# LPC178x7x register map
File version: 0.9
CPU: CM3 r0p0, little endian, no MPU, no FPU, 3 interrupt priority bits
Registers are 32-bit, read-write, reset 0x0 unless marked. A register's access mark holds for its fields unless they carry their own. Offsets are from the block's base; [hi:lo] are bit positions; {n}, {i} and the like mark numbered series.

## SYSCON — System and clock control
Base 0x400FC000
0x00 FLASHCFG — Flash Accelerator Configuration Register. Controls flash access timing.
  [15:12] FLASHTIM — Flash access time. The value of this field plus 1 gives the number of CPU clocks used for a flash access. Warning: improper setting of this value may result in incorrect operation of the device. All other values are reserved.
    0=FLASH_ACCESSES_USE_1 (Flash accesses use 1 CPU clock. Use for up to 20 MHz CPU clock with power boost off.); 1=FLASH_ACCESSES_USE_2 (Flash accesses use 2 CPU clocks. Use for up to 40 MHz CPU clock with power boost off.); 2=FLASH_ACCESSES_USE_3 (Flash accesses use 3 CPU clocks. Use for up to 60 MHz CPU clock with power boost off.); 3=FLASH_ACCESSES_USE_4 (Flash accesses use 4 CPU clocks. Use for up to 80 MHz CPU clock with power boost off. Use this setting for operation from 100 to 120 MHz operation with power boost on.); 4=FLASH_ACCESSES_USE_5 (Flash accesses use 5 CPU clocks. Use for up to 100 MHz CPU clock with power boost off.); 5=FLASH_ACCESSES_USE_6 (Flash accesses use 6 CPU clocks. Safe setting for any allowed conditions.)
{0x80+0x20*i} PLL{i}CON (i=0..1) — PLL0 Control register
  [0] PLLE — PLL Enable. When one, and after a valid PLL feed, this bit will activate the related PLL and allow it to lock to the requested frequency. See PLLSTAT register, Table 12.
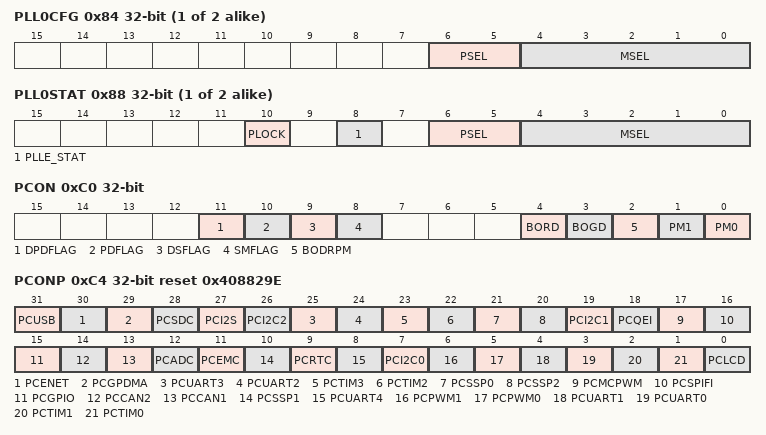
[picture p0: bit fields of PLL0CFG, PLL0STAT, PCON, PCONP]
{0x84+0x20*i} PLL{i}CFG (i=0..1) — PLL0 Configuration register
  [6:5] PSEL — PLL Divider value. Supplies the value "P" in the PLL frequency calculations. Note: For details on selecting the right value for PSEL see Section 3.10.4.
  [4:0] MSEL — PLL Multiplier value. Supplies the value "M" in the PLL frequency calculations. Note: For details on selecting the right value for MSEL see Section 3.10.4.
{0x88+0x20*i} PLL{i}STAT (i=0..1) ro — PLL0 Status register
  [10] PLOCK — Reflects the PLL Lock status. When zero, the related PLL is not locked. When one, the related PLL is locked onto the requested frequency.
  [8] PLLE_STAT — Read-back for the PLL Enable bit. When one, the related PLL is currently activated. When zero, the related PLL is turned off. This bit is automatically cleared when Power-down mode is activated.
  [6:5] PSEL — Read-back for the PLL Divider value. This is the value currently used by the related PLL.
  [4:0] MSEL — Read-back for the PLL Multiplier value. This is the value currently used by the related PLL.
{0x8C+0x20*i} PLL{i}FEED (i=0..1) wo reset not defined — PLL0 Feed register
  [7:0] PLLFEED — The PLL feed sequence must be written to this register in order for the related PLL's configuration and control register changes to take effect.
0xC0 PCON — Power Control register
  [11] DPDFLAG — Deep Power-down entry flag. Set when the Deep Power-down mode is successfully entered. Cleared by software writing a one to this bit.
  [10] PDFLAG — Power-down entry flag. Set when the Power-down mode is successfully entered. Cleared by software writing a one to this bit.
  [9] DSFLAG — Deep Sleep entry flag. Set when the Deep Sleep mode is successfully entered. Cleared by software writing a one to this bit.
  [8] SMFLAG — Sleep Mode entry flag. Set when the Sleep mode is successfully entered. Cleared by software writing a one to this bit.
  [4] BORD — Brown-Out Reset Disable. When BORD is 1, the BOD will not reset the device when the VDD(REG)(3V3) voltage dips goes below the BOD reset trip level. The Brown-Out interrupt is not affected. When BORD is 0, the BOD reset is enabled. See the Section 3.6 for details of Brown-Out detection.
  [3] BOGD — Brown-Out Global Disable. When BOGD is 1, the Brown-Out Detect circuitry is fully disabled at all times, and does not consume power. When 0, the Brown-Out Detect circuitry is enabled. See the System Control Block chapter for details of Brown-Out detection.
  [2] BODRPM — Brown-Out Reduced Power Mode. When BODRPM is 1, the Brown-Out Detect circuitry will be turned off when chip Power-down mode or Deep Sleep mode is entered, resulting in a further reduction in power usage. However, the possibility of using Brown-Out Detect as a wake-up source from the reduced power mode will be lost. When 0, the Brown-Out Detect function remains active during Power-down and Deep Sleep modes. See the System Control Block chapter for details of Brown-Out detection.
  [1] PM1 — Power mode control bit 1. This bit controls entry to the Deep Power-down mode. See Section 3.3.6.1 below for details.
  [0] PM0 — Power mode control bit 0. This bit controls entry to the Power-down mode. See Section 3.3.6.1 below for details.
0xC4 PCONP reset 0x408829E — Power Control for Peripherals
  [31] PCUSB — USB interface power/clock control bit.
  [30] PCENET — Ethernet block power/clock control bit.
  [29] PCGPDMA — GPDMA function power/clock control bit.
  [28] PCSDC — SD Card interface power/clock control bit.
  [27] PCI2S — I2S interface power/clock control bit.
  [26] PCI2C2 — I2C interface 2 power/clock control bit.
  [25] PCUART3 — UART 3 power/clock control bit.
  [24] PCUART2 — UART 2 power/clock control bit.
  [23] PCTIM3 — Timer 3 power/clock control bit.
  [22] PCTIM2 — Timer 2 power/clock control bit.
  [21] PCSSP0 — SSP0 interface power/clock control bit.
  [20] PCSSP2 — SSP2 interface power/clock control bit.
  [19] PCI2C1 — I2C1 interface power/clock control bit.
  [18] PCQEI — Quadrature Encoder Interface power/clock control bit.
  [17] PCMCPWM — Motor Control PWM power/clock control bit.
  [16] PCSPIFI — SPI Flash Interface power/clock control bit (LPC1773 only).
  [15] PCGPIO — Power/clock control bit for IOCON, GPIO, and GPIO interrupts.
  [14] PCCAN2 — CAN Controller 2 power/clock control bit.
  [13] PCCAN1 — CAN Controller 1 power/clock control bit.
  [12] PCADC — A/D converter (ADC) power/clock control bit. Note: Clear the PDN bit in the AD0CR before clearing this bit, and set this bit before attempting to set PDN.
  [11] PCEMC — External Memory Controller power/clock control bit.
  [10] PCSSP1 — SSP 1 interface power/clock control bit.
  [9] PCRTC — RTC and Event Monitor/Recorder power/clock control bit.
  [8] PCUART4 — UART4 power/clock control bit.
  [7] PCI2C0 — I2C0 interface power/clock control bit.
  [6] PCPWM1 — PWM1 power/clock control bit.
  [5] PCPWM0 — PWM0 power/clock control bit.
  [4] PCUART1 — UART1 power/clock control bit.
  [3] PCUART0 — UART0 power/clock control bit.
  [2] PCTIM1 — Timer/Counter 1 power/clock control bit.
  [1] PCTIM0 — Timer/Counter 0 power/clock control bit.
  [0] PCLCD — LCD controller power/clock control bit.
0x100 EMCCLKSEL — External Memory Controller Clock Selection register
  [0] EMCDIV — Selects the EMC clock rate relative to the CPU clock.
    0=THE_EMC_USES_THE_SAM (The EMC uses the same clock as the CPU.); 1=THE_EMC_USES_A_CLOCK (The EMC uses a clock at half the rate of the CPU.)
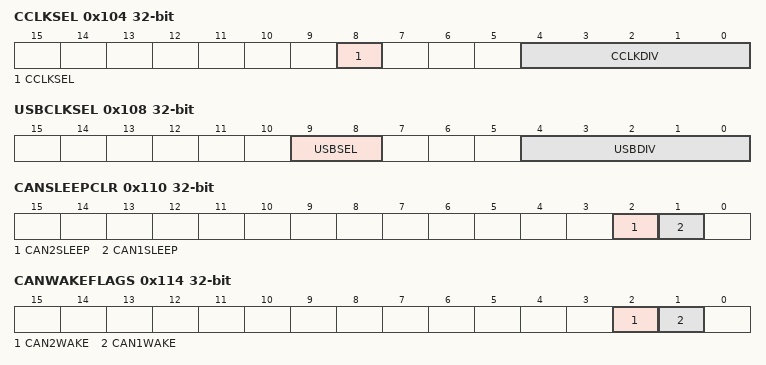
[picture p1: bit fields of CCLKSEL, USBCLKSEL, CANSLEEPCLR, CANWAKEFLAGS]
0x104 CCLKSEL reset not defined — CPU Clock Selection register
  [8] CCLKSEL — Selects the input clock for the CPU clock divider.
    0=SYSCLK_IS_USED_AS_TH (Sysclk is used as the input to the CPU clock divider.); 1=THE_OUTPUT_OF_THE_MA (The output of the Main PLL is used as the input to the CPU clock divider.)
  [4:0] CCLKDIV — Selects the divide value for creating the CPU clock (CCLK) from the selected clock source. 0 = The divider is turned off., no clock will be provided to the CPU. This setting should typically not be used, the CPU will be halted and a reset will be required to restore operation. 1 = The input clock is divided by 1 to produce the CPU clock. 2 = The input clock is divided by 2 to produce the CPU clock. 3 = The input clock is divided by 3 to produce the CPU clock. ... 31 = The input clock is divided by 31 to produce the CPU clock.
0x108 USBCLKSEL — USB Clock Selection register
  [9:8] USBSEL — Selects the input clock for the USB clock divider.
    0=SYSCLK_IS_USED_AS_TH (Sysclk is used as the input to the USB clock divider. When this clock is selected, the USB can be accessed by software but cannot perform USB functions.); 1=THE_OUTPUT_OF_THE_MA (The output of the Main PLL is used as the input to the USB clock divider.); 2=THE_OUTPUT_OF_THE_AL (The output of the Alt PLL is used as the input to the USB clock divider.)
  [4:0] USBDIV — Selects the divide value for creating the USB clock from the selected PLL output. Only the values shown below can produce even number multiples of 48 MHz from the PLL. Warning: Improper setting of this value will result in incorrect operation of the USB interface. Only the main oscillator in conjunction with either PLL0 or PLL1 can provide a clock that meets USB accuracy and jitter specifications. Other values cannot produce the 48 MHz clock required for USB operation.
    0=THE_DIVIDER_IS_TURNE (The divider is turned off, no clock will be provided to the USB subsystem.); 4=PLL0_OUTPUT_IS_DIVID (PLL0 output is divided by 4. PLL0 output must be 192 MHz.); 6=PLL0_OUTPUT_IS_DIVID (PLL0 output is divided by 6. PLL0 output must be 288 MHz.)
0x10C CLKSRCSEL — Clock Source Select Register
  [0] CLKSRC — Selects the clock source for sysclk and PLL0 as follows:
    0=SELECTS_THE_INTERNAL (Selects the Internal RC oscillator as the sysclk and PLL0 clock source (default).); 1=SELECTS_THE_MAIN_OSC (Selects the main oscillator as the sysclk and PLL0 clock source.)
0x110 CANSLEEPCLR — Allows clearing the current CAN channel sleep state as well as reading that state.
  [2] CAN2SLEEP — Sleep status and control for CAN channel 2. Read: when 1, indicates that CAN channel 2 is in the sleep mode. Write: writing a 1 causes clocks to be restored to CAN channel 2.
  [1] CAN1SLEEP — Sleep status and control for CAN channel 1. Read: when 1, indicates that CAN channel 1 is in the sleep mode. Write: writing a 1 causes clocks to be restored to CAN channel 1.
0x114 CANWAKEFLAGS — Allows reading the wake-up state of the CAN channels.
  [2] CAN2WAKE — Wake-up status for CAN channel 2. Read: when 1, indicates that a falling edge has occurred on the receive data line of CAN channel 2. Write: writing a 1 clears this bit.
  [1] CAN1WAKE — Wake-up status for CAN channel 1. Read: when 1, indicates that a falling edge has occurred on the receive data line of CAN channel 1. Write: writing a 1 clears this bit.
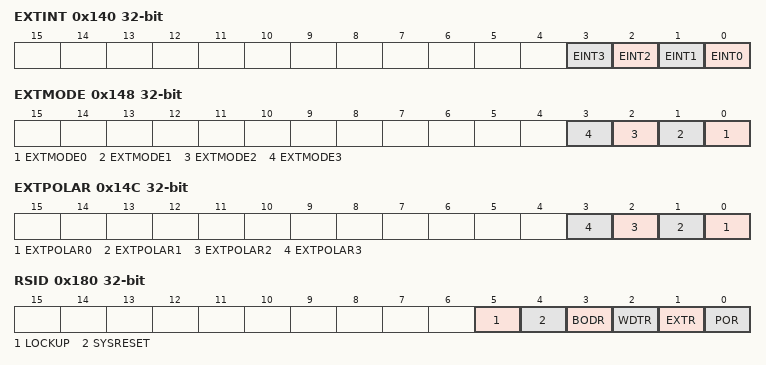
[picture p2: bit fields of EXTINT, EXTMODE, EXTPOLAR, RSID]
0x140 EXTINT — External Interrupt Flag Register
  [n] EINT{n} (n=0..3) — In level-sensitive mode, this bit is set if the EINT{n} function is selected for its pin, and the pin is in its active state. In edge-sensitive mode, this bit is set if the EINT{n} function is selected for its pin, and the selected edge occurs on the pin. This bit is cleared by writing a one to it, except in level sensitive mode when the pin is in its active state.[1]
0x148 EXTMODE — External Interrupt Mode register
  [all] fields
    0=LEVEL_SENSITIVE_; 1=EDGE_SENSITIVE_
  [n] EXTMODE{n} (n=0..3) — Level or edge sensitivity select for EINT{n}.
0x14C EXTPOLAR — External Interrupt Polarity Register
  [n] EXTPOLAR{n} (n=0..3) — External interrupt polarity for EINT{n}.
    0=LOW_ACTIVE_OR_FALLIN (Low-active or falling-edge sensitive (depending on EXTMODE{n}).); 1=HIGH_ACTIVE_OR_RISIN (High-active or rising-edge sensitive (depending on EXTMODE{n}).)
0x180 RSID reset not defined — Reset Source Identification Register
  [5] LOCKUP — This bit is set if the processor has been reset due to a lockup, as described in Section 40.3.4.4 Lockup. The lockup state causes a chip reset in the LPC178x/177x. This bit is cleared only by software or POR.
  [4] SYSRESET — This bit is set if the processor has been reset due to a system reset request, as described in Section 40.4.3.6 Application Interrupt and Reset Control Register. Setting the SYSRESETREQ bit in the Cortex-M3 AIRCR register causes a chip reset in the LPC178x/177x. This bit is cleared only by software or POR.
  [3] BODR — This bit is set when the VDD(REG)(3V3) voltage reaches a level below the BOD reset trip level (typically 1.85 V under nominal room temperature conditions). If the VDD(REG)(3V3) voltage dips from the normal operating range to below the BOD reset trip level and recovers, the BODR bit will be set to 1. If the VDD(REG)(3V3) voltage dips from the normal operating range to below the BOD reset trip level and continues to decline to the level at which POR is asserted (nominally 1 V), the BODR bit is cleared. If the VDD(REG)(3V3) voltage rises continuously from below 1 V to a level above the BOD reset trip level, the BODR will be set to 1. This bit is cleared only by software or POR. Note: Only in the case where a reset occurs and the POR = 0, the BODR bit indicates if the VDD(REG)(3V3) voltage was below the BOD reset trip level or not.
  [2] WDTR — This bit is set when the Watchdog Timer times out and the WDTRESET bit in the Watchdog Mode Register is 1. This bit is cleared only by software or POR.
  [1] EXTR — Assertion of the external RESET signal sets this bit. This bit is cleared only by software or POR.
  [0] POR — Assertion of the POR signal sets this bit, and clears all of the other bits in this register. But if another Reset signal (e.g., External Reset) remains asserted after the POR signal is negated, then its bit is set. This bit is not affected by any of the other sources of Reset.
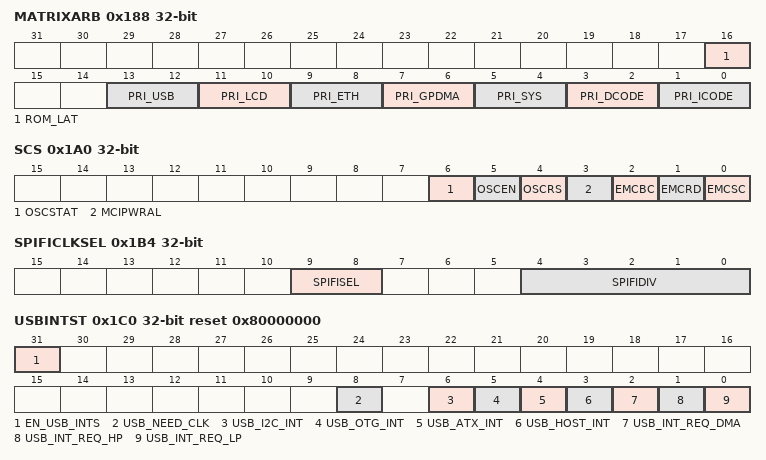
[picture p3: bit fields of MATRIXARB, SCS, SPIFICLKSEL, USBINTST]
0x188 MATRIXARB reset not defined — Matrix arbitration register
  [16] ROM_LAT — ROM latency select. Should always be 0.
  [13:12] PRI_USB — USB DMA priority.
  [11:10] PRI_LCD — LCD DMA priority.
  [9:8] PRI_ETH — Ethernet DMA priority.
  [7:6] PRI_GPDMA — General Purpose DMA controller priority.
  [5:4] PRI_SYS — System bus priority.
  [3:2] PRI_DCODE — D-Code bus priority.
  [1:0] PRI_ICODE — I-Code bus priority. Should be lower than PRI_DCODE for proper operation.
0x1A0 SCS — System Control and Status
  [6] OSCSTAT — Main oscillator status.
    0=THE_MAIN_OSCILLATOR_ (The main oscillator is not ready to be used as a clock source.); 1=THE_MAIN_OSCILLATOR_ (The main oscillator is ready to be used as a clock source. The main oscillator must be enabled via the OSCEN bit.)
  [5] OSCEN — Main oscillator enable.
    0=THE_MAIN_OSCILLATOR_ (The main oscillator is disabled.); 1=THE_MAIN_OSCILLATOR_ (The main oscillator is enabled, and will start up if the correct external circuitry is connected to the XTAL1 and XTAL2 pins.)
  [4] OSCRS — Main oscillator range select.
    0=THE_FREQUENCY_RANGE_ (The frequency range of the main oscillator is 1 MHz to 20 MHz.); 1=THE_FREQUENCY_RANGE_ (The frequency range of the main oscillator is 15 MHz to 25 MHz.)
  [3] MCIPWRAL — MCIPWR Active Level[1]. Selects the active level of the SD card interface signal SD_PWR.
    0=SD_PWR_IS_ACTIVE_LOW (SD_PWR is active low (inverted output of the SD Card interface block).); 1=SD_PWR_IS_ACTIVE_HIG (SD_PWR is active high (follows the output of the SD Card interface block).)
  [2] EMCBC — External Memory Controller burst control. Also see Section 10.10 in the EMC chapter.
    0=BURST_ENABLED_; 1=BURST_DISABLED_THIS (Burst disabled. This mode can be used to prevent multiple sequential accesses to memory mapped I/O devices connected to EMC static memory chip selects. These unrequested accesses can cause issues with some I/O devices.)
  [1] EMCRD — EMC Reset Disable[1]. External Memory Controller Reset Disable. Also see Section 10.8 in the EMC chapter.
    0=BOTH_EMC_RESETS_ARE_ (Both EMC resets are asserted when any type of chip reset event occurs. In this mode, all registers and functions of the EMC are initialized upon any reset condition.); 1=MANY_PORTIONS_OF_THE (Many portions of the EMC are only reset by a power-on or brown-out event, in order to allow the EMC to retain its state through a warm reset (external reset or watchdog reset). If the EMC is configured correctly, auto-refresh can be maintained through a warm reset.)
  [0] EMCSC — EMC Shift Control. Controls how addresses are output on the EMC address pins for static memories. Also see Section 10.9 in the EMC chapter.
    0=STATIC_MEMORY_ADDRES (Static memory addresses are shifted to match the data bus width. For example, when accessing a 32-bit wide data bus, the address is shifted right 2 places such that bit 2 is the LSB. In this mode, address bit 0 for the this device is connected to address bit 0 of the memory device, thus simplifying memory connections. This also makes a larger memory address range possible, because additional upper address bits can appear on the higher address pins due to the shift.); 1=STATIC_MEMORY_ADDRES (Static memory addresses are always output as byte addresses regardless of the data bus width. For example, when word data is accessed on a 32-bit bus, address bits 1 and 0 will always be 0. In this mode, one or both lower address bits may not be connected to memories that are part of a bus that is wider than 8 bits. This mode matches the operation of LPC23xx and LPC24xx devices.)
0x1A8 PCLKSEL reset 0x10 — Peripheral Clock Selection register
  [4:0] PCLKDIV — Selects the divide value for the clock used for all APB peripherals. 0 = The divider is turned off., no clock will be provided to APB peripherals.. 1 = The input clock is divided by 1 to produce the APB peripheral clock. 2 = The input clock is divided by 2 to produce the APB peripheral clock. 3 = The input clock is divided by 3 to produce the APB peripheral clock. ... 31 = The input clock is divided by 31 to produce the APB peripheral clock.
0x1B0 PBOOST reset not defined — Power boost register
  [1:0] Boost — Boost control bits. 00 : Boost is off, operation must be below 100 MHz. 11 : Boost is on, operation up to 120 MHz is supported. Other values are not allowed.
0x1B4 SPIFICLKSEL — SPIFI Clock Selection register
  [9:8] SPIFISEL — Selects the input clock for the USB clock divider.
    0=SYSCLK_IS_USED_AS_TH (Sysclk is used as the input to the SPIFI clock divider.); 1=THE_OUTPUT_OF_THE_MA (The output of the Main PLL is used as the input to the SPIFI clock divider.); 2=THE_OUTPUT_OF_THE_AL (The output of the Alt PLL is used as the input to the SPIFI clock divider.)
  [4:0] SPIFIDIV — Selects the divide value for creating the SPIFI clock from the selected clock source. 0 = The divider is turned off., no clock will be provided to the SPIFI. 1 = The input clock is divided by 1 to produce the SPIFI clock. 2 = The input clock is divided by 2 to produce the SPIFI clock. 3 = The input clock is divided by 3 to produce the SPIFI clock. ... 31 = The input clock is divided by 31 to produce the SPIFI clock.
0x1B8 LCD_CFG — LCD Clock configuration register
  [4:0] CLKDIV — LCD panel clock prescaler selection. The value in the this register plus 1 is used to divide the selected input clock (see the CLKSEL bit in the LCD_POL register), to produce the panel clock.
0x1C0 USBINTST reset 0x80000000 — USB Interrupt Status
  [31] EN_USB_INTS — Enable all USB interrupts. When this bit is cleared, the NVIC does not see the ORed output of the USB interrupt lines.
  [8] USB_NEED_CLK — USB need clock indicator. This bit is read-only. This bit is set to 1 when USB activity or a change of state on the USB data pins is detected, and it indicates that a PLL supplied clock of 48 MHz is needed. Once USB_NEED_CLK becomes one, it resets to zero 5 ms after the last packet has been received/sent, or 2 ms after the Suspend Change (SUS_CH) interrupt has occurred. A change of this bit from 0 to 1 can wake up the microcontroller if activity on the USB bus is selected to wake up the part from the Power-down mode (see Section 4.7.9 Wake-up from Reduced Power Modes for details). Also see Section 4.5.8 PLLs and Power-down mode and Section 4.7.10 Power Control for Peripherals register (PCONP - 0x400F C0C4) for considerations about the PLL and invoking the Power-down mode. This bit is read-only.
  [6] USB_I2C_INT — I2C module interrupt line status. This bit is read-only.
  [5] USB_OTG_INT — OTG interrupt line status. This bit is read-only.
  [4] USB_ATX_INT — External ATX interrupt line status. This bit is read-only.
  [3] USB_HOST_INT — USB host interrupt line status. This bit is read-only.
  [2] USB_INT_REQ_DMA — DMA interrupt line status. This bit is read-only.
  [1] USB_INT_REQ_HP — High priority interrupt line status. This bit is read-only.
  [0] USB_INT_REQ_LP — Low priority interrupt line status. This bit is read-only.
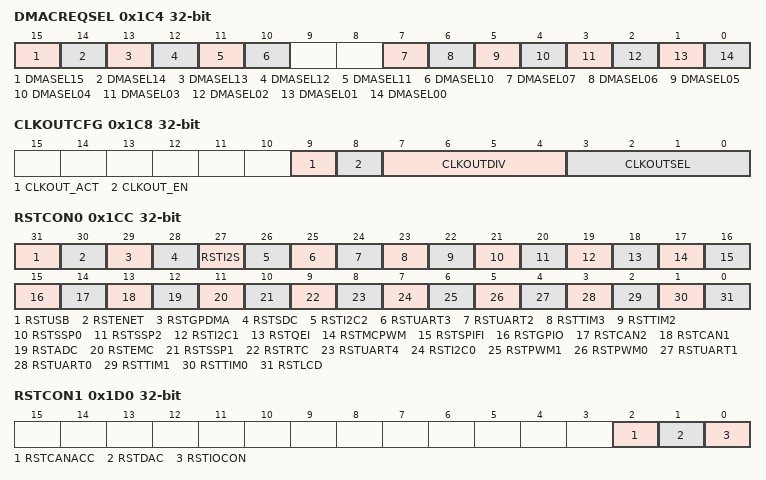
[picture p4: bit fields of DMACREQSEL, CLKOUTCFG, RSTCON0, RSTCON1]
0x1C4 DMACREQSEL — Selects between alternative requests on DMA channels 0 through 7 and 10 through 15
  [15] DMASEL15 — Selects the DMA request for GPDMA input 15: 0 - UART2 receive is selected. 1 - Timer 3 match 1 is selected.
  [14] DMASEL14 — Selects the DMA request for GPDMA input 14: 0 - UART2 transmit is selected. 1 - Timer 3 match 0 is selected.
  [13] DMASEL13 — Selects the DMA request for GPDMA input 13: 0 - UART1 receive is selected. 1 - UART4 receive is selected.
  [12] DMASEL12 — Selects the DMA request for GPDMA input 12: 0 - UART1 transmit is selected. 1 - UART4 transmit is selected.
  [11] DMASEL11 — Selects the DMA request for GPDMA input 11: 0 - UART0 receive is selected. 1 - UART3 receive is selected.
  [10] DMASEL10 — Selects the DMA request for GPDMA input 10: 0 - UART0 transmit is selected. 1 - UART3 transmit is selected.
  [7] DMASEL07 — Selects the DMA request for GPDMA input 7: 0 - SSP2 receive is selected. 1 - I2S channel 1 is selected.
  [6] DMASEL06 — Selects the DMA request for GPDMA input 6: 0 - SSP2 transmit is selected. 1 - I2S channel 0 is selected.
  [5] DMASEL05 — Selects the DMA request for GPDMA input 5: 0 - SSP1 receive is selected. 1 - Timer 2 match 1 is selected.
  [4] DMASEL04 — Selects the DMA request for GPDMA input 4: 0 - SSP1 transmit is selected. 1 - Timer 2 match 0 is selected.
  [3] DMASEL03 — Selects the DMA request for GPDMA input 3: 0 - SSP0 receive is selected. 1 - Timer 1 match 1 is selected.
  [2] DMASEL02 — Selects the DMA request for GPDMA input 2: 0 - SSP0 transmit is selected. 1 - Timer 1 match 0 is selected.
  [1] DMASEL01 — Selects the DMA request for GPDMA input 1: 0 - SD card interface is selected. 1 - Timer 0 match 1 is selected.
  [0] DMASEL00 — Selects the DMA request for GPDMA input 0: 0 - (unused) 1 - Timer 0 match 0 is selected.
0x1C8 CLKOUTCFG — Clock Output Configuration register
  [9] CLKOUT_ACT — CLKOUT activity indication. Reads as 1 when CLKOUT is enabled. Read as 0 when CLKOUT has been disabled via the CLKOUT_EN bit and the clock has completed being stopped.
  [8] CLKOUT_EN — CLKOUT enable control, allows switching the CLKOUT source without glitches. Clear to stop CLKOUT on the next falling edge. Set to enable CLKOUT.
  [7:4] CLKOUTDIV — Integer value to divide the output clock by, minus one. 0x0 = Clock is divided by 1. 0x1 = Clock is divided by 2. 0x2 = Clock is divided by 3. ... 0xF = Clock is divided by 16.
  [3:0] CLKOUTSEL — Selects the clock source for the CLKOUT function. 0x0 = Selects the CPU clock as the CLKOUT source. 0x1 = Selects the main oscillator as the CLKOUT source. 0x2 = Selects the Internal RC oscillator as the CLKOUT source. 0x3 = Selects the USB clock as the CLKOUT source. 0x4 = Selects the RTC oscillator as the CLKOUT source. 0x5 = Selects the SPIFI clock as the CLKOUT source. 0x6 = Selects the Watchdog oscillator as the CLKOUT source. Other settings are reserved. Do not use.
0x1CC RSTCON0 — Individual peripheral reset control bits
  [31] RSTUSB — USB interface reset control bit.
  [30] RSTENET — Ethernet block reset control bit.
  [29] RSTGPDMA — GPDMA function reset control bit.
  [28] RSTSDC — SD Card interface reset control bit.
  [27] RSTI2S — I2S interface reset control bit.
  [26] RSTI2C2 — I2C interface 2 reset control bit.
  [25] RSTUART3 — UART 3 reset control bit.
  [24] RSTUART2 — UART 2 reset control bit.
  [23] RSTTIM3 — Timer 3 reset control bit.
  [22] RSTTIM2 — Timer 2 reset control bit.
  [21] RSTSSP0 — The SSP0 interface reset control bit.
  [20] RSTSSP2 — The SSP2 interface reset control bit.
  [19] RSTI2C1 — The I2C1 interface reset control bit.
  [18] RSTQEI — Quadrature Encoder Interface reset control bit.
  [17] RSTMCPWM — Motor Control PWM reset control bit.
  [16] RSTSPIFI — SPI Flash Interface reset control bit (LPC1773 only).
  [15] RSTGPIO — Reset control bit for GPIO, and GPIO interrupts. Note: IOCON may be reset by a separate bit in the RSTCON1 register.
  [14] RSTCAN2 — CAN Controller 2 reset control bit. Note: The CAN acceptance filter may be reset by a separate bit in the RSTCON1 register.
  [13] RSTCAN1 — CAN Controller 1 reset control bit. Note: The CAN acceptance filter may be reset by a separate bit in the RSTCON1 register.
  [12] RSTADC — A/D converter (ADC) reset control bit.
  [11] RSTEMC — External Memory Controller reset control bit.
  [10] RSTSSP1 — The SSP 1 interface reset control bit.
  [9] RSTRTC — RTC and Event Monitor/Recorder reset control bit. RTC reset is limited, see Table 628 Real-Time Clock register map for details.
  [8] RSTUART4 — UART4 reset control bit.
  [7] RSTI2C0 — The I2C0 interface reset control bit.
  [6] RSTPWM1 — PWM1 reset control bit.
  [5] RSTPWM0 — PWM0 reset control bit.
  [4] RSTUART1 — UART1 reset control bit.
  [3] RSTUART0 — UART0 reset control bit.
  [2] RSTTIM1 — Timer/Counter 1 reset control bit.
  [1] RSTTIM0 — Timer/Counter 0 reset control bit.
  [0] RSTLCD — LCD controller reset control bit.
0x1D0 RSTCON1 — Individual peripheral reset control bits
  [2] RSTCANACC — CAN acceptance filter reset control bit.
  [1] RSTDAC — D/A converter (DAC) reset control bit.
  [0] RSTIOCON — Reset control bit for the IOCON registers.
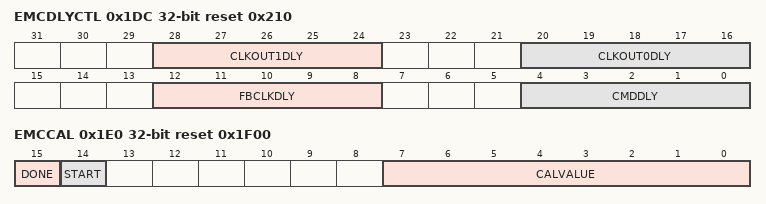
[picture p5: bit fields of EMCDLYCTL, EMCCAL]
0x1DC EMCDLYCTL reset 0x210 — Values for the 4 programmable delays associated with SDRAM operation.
  [28:24] CLKOUT1DLY — Programmable delay value for the CLKOUT1 output. This would typically be used in clock delayed mode. See Section 10.12.6 The delay amount is roughly (CLKOUT1DLY+1) * 250 picoseconds.
  [20:16] CLKOUT0DLY — Programmable delay value for the CLKOUT0 output. This would typically be used in clock delayed mode. See Section 10.12.6 The delay amount is roughly (CLKOUT0DLY+1) * 250 picoseconds. Delaying the clock output changes dynamic characteristics defined in the device data sheet.
  [12:8] FBCLKDLY — Programmable delay value for the feedback clock that controls input data sampling. See Section 10.5.3. The delay amount is roughly (FBCLKDLY+1) * 250 picoseconds.
  [4:0] CMDDLY — Programmable delay value for EMC outputs in command delayed mode. See Section 10.12.6. The delay amount is roughly (CMDDLY+1) * 250 picoseconds. This field applies only when the command delayed read strategy is selected in the EMCDynamicReadConfig register. In this mode, all control outputs from the EMC are delayed, but the output clock is not. Delaying the control outputs changes dynamic characteristics defined in the device data sheet.
0x1E0 EMCCAL reset 0x1F00 — Controls the calibration counter for programmable delays and returns the result value.
  [15] DONE — Measurement completion flag. this bit is set when a calibration measurement is completed. This bit is cleared automatically when the START bit is set.
  [14] START — Start control bit for the EMC calibration counter. Writing a 1 to this bit begins the measurement process. This bit is cleared automatically when the measurement is complete.
  [7:0] CALVALUE — Returns the count of the approximately 50 MHz ring oscillator that occur during 32 clocks of the IRC oscillator. This represents the composite effect of processing variation, internal regulator supply voltage, and ambient temperature.
